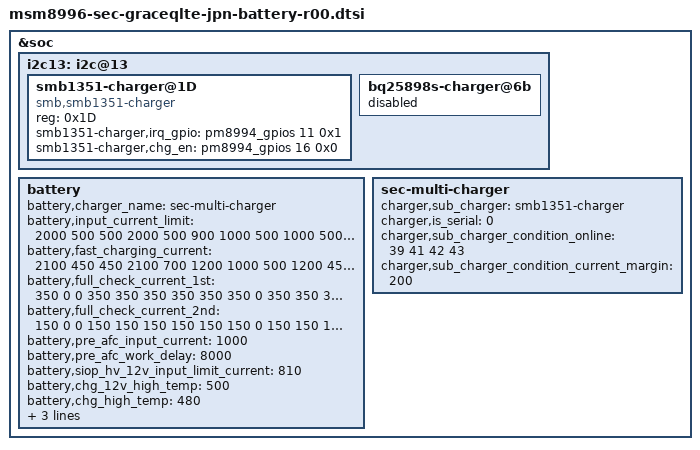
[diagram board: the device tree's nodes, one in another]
/* Copyright (c) 2014, The Linux Foundation. All rights reserved.
 *
 * This program is free software; you can redistribute it and/or modify
 * it under the terms of the GNU General Public License version 2 and
 * only version 2 as published by the Free Software Foundation.
 *
 * This program is distributed in the hope that it will be useful,
 * but WITHOUT ANY WARRANTY; without even the implied warranty of
 * MERCHANTABILITY or FITNESS FOR A PARTICULAR PURPOSE.  See the
 * GNU General Public License for more details.
 */
#include "msm8996-sec-graceqlte-common-battery.dtsi"
&soc {
	i2c13: i2c@13 {
		smb1351-charger@1D {
			status = "okay";
			compatible = "smb,smb1351-charger";
			reg = <0x1D>;
			smb1351-charger,irq_gpio = <&pm8994_gpios 11 0x1>;
			smb1351-charger,chg_en = <&pm8994_gpios 16 0x0>;
		};

		bq25898s-charger@6b {
			status = "disabled";
		};
	};

	battery {
		battery,charger_name = "sec-multi-charger";
		battery,input_current_limit = <2000 500 500 2000 500 900 1000 500 1000 500 900 1900 1800 500 500 400 700 1300 300 1000 1500 500 1667 1000 1667 80 1800 1667 1400 1000 1000 500 900 900 700 900 900 900 2100 500 1667 1667 3000>;
		battery,fast_charging_current = <2100 450 450 2100 700 1200 1000 500 1200 450 2100 1600 2100 450 450 400 700 1300 300 1000 1500 450 3000 1000 3000 80 1800 1000 1400 450 1000 500 2100 2100 2100 2100 2100 2100 3500 450 3000 3000 3000>;
		battery,full_check_current_1st = <350 0 0 350 350 350 350 350 350 0 350 350 350 0 0 350 350 350 350 350 350 0 350 350 350 0 350 350 350 0 350 0 350 350 350 350 350 350 350 350 350 350 350>;
		battery,full_check_current_2nd = <150 0 0 150 150 150 150 150 150 0 150 150 150 0 0 150 150 150 150 150 150 0 150 150 150 0 150 150 150 0 150 0 150 150 150 150 150 150 150 150 150 150 150>;
		battery,pre_afc_input_current = <1000>;
		battery,pre_afc_work_delay = <8000>;
		battery,siop_hv_12v_input_limit_current = <810>;

		battery,chg_12v_high_temp = <500>;
		battery,chg_high_temp = <480>;
		battery,chg_high_temp_recovery = <470>;

		battery,qc_step_charging_current = <3600 3000>;
		battery,cisd_chg_limit_enable;
	};

	sec-multi-charger {
		charger,sub_charger = "smb1351-charger";
		charger,is_serial = <0>;
		charger,sub_charger_condition_online = <39 41 42 43>;
		charger,sub_charger_condition_current_margin = <200>;
	};
};
